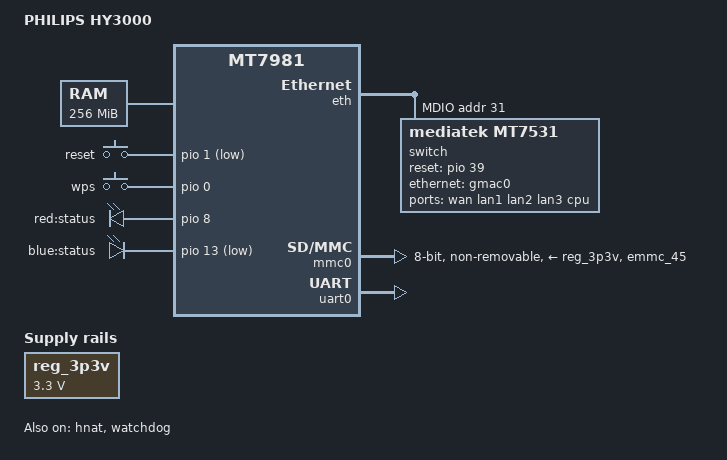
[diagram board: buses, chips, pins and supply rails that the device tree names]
// SPDX-License-Identifier: GPL-2.0-or-later OR MIT
/*
 * Copyright (C) 2023 Tianling Shen <cnsztl@immortalwrt.org>
 */

/dts-v1/;

#include <dt-bindings/gpio/gpio.h>
#include <dt-bindings/input/input.h>

#include "mt7981.dtsi"

/ {
	model = "PHILIPS HY3000";
	compatible = "philips,hy3000", "mediatek,mt7981";

	aliases {
		led-boot = &status_red_led;
		led-failsafe = &status_blue_led;
		led-running = &status_blue_led;
		led-upgrade = &status_blue_led;
	};

	chosen {
		bootargs = "console=ttyS0,115200n1 loglevel=8 \
			    earlycon=uart8250,mmio32,0x11002000 \
			    root=PARTLABEL=rootfs rootfstype=squashfs,f2fs";
	};

	memory {
		reg = <0 0x40000000 0 0x10000000>;
	};

	gpio-keys {
		compatible = "gpio-keys";

		button-reset {
			label = "reset";
			linux,code = <KEY_RESTART>;
			gpios = <&pio 1 GPIO_ACTIVE_LOW>;
		};

		button-wps {
			label = "wps";
			linux,code = <KEY_WPS_BUTTON>;
			gpios = <&pio 0 GPIO_ACTIVE_HIGH>;
		};
	};

	gpio-leds {
		compatible = "gpio-leds";

		status_red_led: led-0 {
			label = "red:status";
			gpios = <&pio 8 GPIO_ACTIVE_HIGH>;
		};

		status_blue_led: led-1 {
			label = "blue:status";
			gpios = <&pio 13 GPIO_ACTIVE_LOW>;
		};
	};

	reg_3p3v: regulator-3p3v {
		compatible = "regulator-fixed";
		regulator-name = "fixed-3.3V";
		regulator-min-microvolt = <3300000>;
		regulator-max-microvolt = <3300000>;
		regulator-boot-on;
		regulator-always-on;
	};

};

&eth {
	status = "okay";

	gmac0: mac@0 {
		compatible = "mediatek,eth-mac";
		reg = <0>;
		phy-mode = "2500base-x";

		fixed-link {
			speed = <2500>;
			full-duplex;
			pause;
		};
	};

	gmac1: mac@1 {
		compatible = "mediatek,eth-mac";
		reg = <1>;
		phy-mode = "2500base-x";

		fixed-link {
			speed = <2500>;
			full-duplex;
			pause;
		};
	};

	mdio: mdio-bus {
		#address-cells = <1>;
		#size-cells = <0>;
		
		switch@0 {
			compatible = "mediatek,mt7531";
			reg = <31>;
			reset-gpios = <&pio 39 0>;

			ports {
				#address-cells = <1>;
				#size-cells = <0>;

				port@0 {
					reg = <0>;
					label = "wan";
				};

				port@1 {
					reg = <1>;
					label = "lan1";
				};

				port@2 {
					reg = <2>;
					label = "lan2";
				};

				port@3 {
					reg = <3>;
					label = "lan3";
				};

				port@6 {
					reg = <6>;
					label = "cpu";
					ethernet = <&gmac0>;
					phy-mode = "2500base-x";

					fixed-link {
						speed = <2500>;
						full-duplex;
						pause;
					};
				};
			};
		};
	};
};



&hnat {
	mtketh-wan = "eth1";
	mtketh-lan = "lan";
	mtketh-ppd = "eth1";
	mtketh-max-gmac = <2>;
	status = "okay";
};

&mmc0 {
	bus-width = <8>;
	cap-mmc-highspeed;
	max-frequency = <52000000>;
	no-sd;
	no-sdio;
	non-removable;
	pinctrl-names = "default", "state_uhs";
	pinctrl-0 = <&mmc0_pins_default>;
	pinctrl-1 = <&mmc0_pins_uhs>;
	vmmc-supply = <&reg_3p3v>;
	non-removable;
	status = "okay";
};

&pio {
	spic_pins: spi1-pins {
		mux {
			function = "spi";
			groups = "spi1_1";
		};
	};

	spi2_flash_pins: spi2-pins {
		mux {
			function = "spi";
			groups = "spi2", "spi2_wp_hold";
		};

		conf-pu {
			pins = "SPI2_CS", "SPI2_HOLD", "SPI2_WP";
			drive-strength = <MTK_DRIVE_8mA>;
			bias-pull-up = <MTK_PUPD_SET_R1R0_11>;
		};

		conf-pd {
			pins = "SPI2_CLK", "SPI2_MOSI", "SPI2_MISO";
			drive-strength = <MTK_DRIVE_8mA>;
			bias-pull-down = <MTK_PUPD_SET_R1R0_11>;
		};
	};

	mmc0_pins_default: mmc0-pins-default {
		mux {
			function = "flash";
			groups = "emmc_45";
		};
	};

	mmc0_pins_uhs: mmc0-pins-uhs {
		mux {
			function = "flash";
			groups = "emmc_45";
		};
	};
};

&uart0 {
	status = "okay";
};

&watchdog {
	status = "okay";
};

&xhci {
	status = "disabled";
};
